# LPC11U6x register map
File version: 0.8
CPU: CM0PLUS r0p1, little endian, no MPU, no FPU, 2 interrupt priority bits
Registers are 32-bit, read-write, reset 0x0 unless marked. A register's access mark holds for its fields unless they carry their own. Offsets are from the block's base; [hi:lo] are bit positions; {n}, {i} and the like mark numbered series; 'fields as' and 'values as' point back to an identical list.

## SYSCON — System configuration (SYSCON)
Base 0x40048000
0x00 SYSMEMREMAP — System memory remap
  [1:0] MAP — System memory remap. Value 0x3 is reserved.
    0=BOOT_LOADER_MODE (Boot Loader Mode. Interrupt vectors are re-mapped to Boot ROM.); 1=USER_RAM_MODE (User RAM Mode. Interrupt vectors are re-mapped to Static RAM.); 2=USER_FLASH_MODE (User Flash Mode. Interrupt vectors are not re-mapped and reside in Flash.)
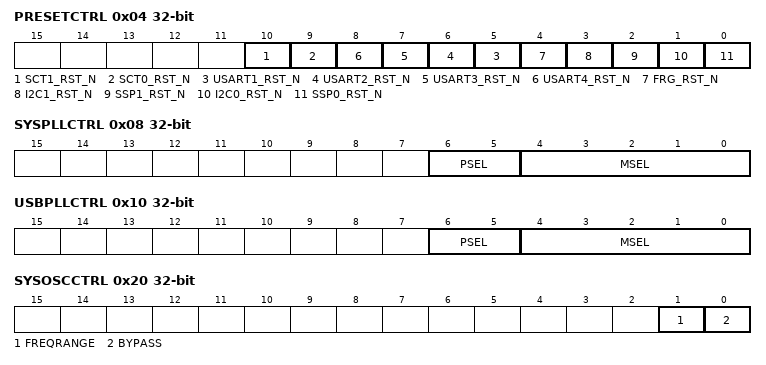
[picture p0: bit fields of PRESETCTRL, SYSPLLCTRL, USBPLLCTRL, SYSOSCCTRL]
0x04 PRESETCTRL — Peripheral reset control
  [10] SCT1_RST_N — SCT1 reset control
    0=RESET (Reset. Resets the SCT1 peripheral.); 1=CLEAR_RESET (Clear reset. SCT1 reset de-asserted.)
  [9] SCT0_RST_N — SCT0 reset control
    0=RESET (Reset. Resets the SCT0 peripheral.); 1=CLEAR_RESET (Clear reset. SCT0 reset de-asserted.)
  [n+4] USART{n}_RST_N (n=1..4) — USART{n} reset control
    0=RESET (Reset. Resets the USART{n} peripheral.); 1=CLEAR_RESET (Clear reset. USART{n} reset de-asserted.)
  [4] FRG_RST_N — FRG reset control
    0=RESET (Reset. Resets the FRG peripheral.); 1=CLEAR_RESET (Clear reset. FRG reset de-asserted.)
  [3] I2C1_RST_N — I2C1 reset control
    0=RESET (Reset. Resets the I2C1 peripheral.); 1=CLEAR_RESET (Clear reset. I2C1 reset de-asserted.)
  [2] SSP1_RST_N — SSP1 reset control
    0=RESET (Reset. Resets the SSP1 peripheral.); 1=CLEAR_RESET (Clear reset. SSP1 reset de-asserted.)
  [1] I2C0_RST_N — I2C0 reset control
    0=RESET (Reset. Resets the I2C0 peripheral.); 1=CLEAR_RESET (Clear reset. I2C0 reset de-asserted.)
  [0] SSP0_RST_N — SSP0 reset control
    0=RESET (Reset. Resets the SSP0 peripheral.); 1=CLEAR_RESET (Clear reset. SSP0 reset de-asserted.)
0x08 SYSPLLCTRL — System PLL control
  [6:5] PSEL — Post divider ratio P. The division ratio is 2 x P.
    0=P_EQ_1 (P = 1); 1=P_EQ_2 (P = 2); 2=P_EQ_4 (P = 4); 3=P_EQ_8 (P = 8)
  [4:0] MSEL — Feedback divider value. The division value M is the programmed MSEL value + 1. 00000: Division ratio M = 1 to 11111: Division ratio M = 32
0x0C SYSPLLSTAT ro — System PLL status
  [0] LOCK — PLL lock status
    0=NO_LOCK (No lock. PLL not locked); 1=LOCK (Lock. PLL locked)
0x10 USBPLLCTRL — USB PLL control
  fields as SYSPLLCTRL
0x14 USBPLLSTAT ro — USB PLL status
  fields as SYSPLLSTAT
0x1C RTCOSCCTRL reset 0x1 — RTC oscillator 32 kHz output control
  [0] RTCOSCEN — Enable the RTC 32 kHz output.
    0=DISABLED (Disabled. 32 kHz output disabled.); 1=ENABLED (Enabled. 32 kHz output enabled.)
0x20 SYSOSCCTRL — System oscillator control
  [1] FREQRANGE — Determines frequency range for Low-power oscillator.
    0=LOW (Low. 1 - 20 MHz frequency range.); 1=HIGH (High. 15 - 25 MHz frequency range.)
  [0] BYPASS — Bypass system oscillator
    0=OSCILLATOR_IS_NOT_BY (Oscillator is not bypassed.); 1=BYPASS_ENABLED (Bypass enabled. PLL input (sys_osc_clk) is fed directly from the XTALIN pin bypassing the oscillator. Use this mode when using an external clock source instead of the crystal oscillator.)
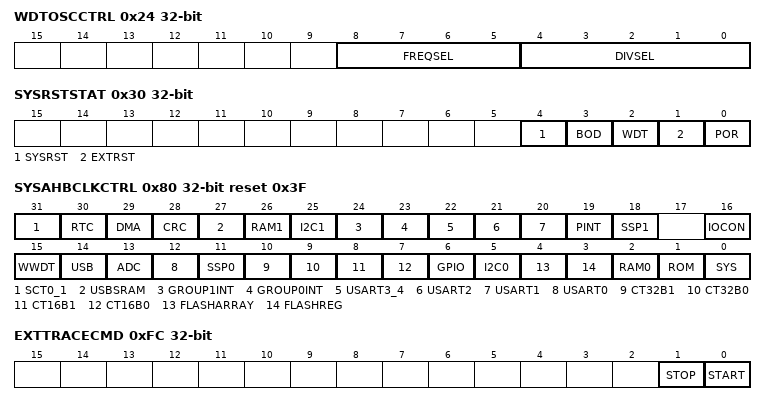
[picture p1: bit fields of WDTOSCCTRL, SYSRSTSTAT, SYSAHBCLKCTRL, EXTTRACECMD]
0x24 WDTOSCCTRL — Watchdog oscillator control
  [8:5] FREQSEL — Select watchdog oscillator analog output frequency (Fclkana).
    1=600KHz (0.6 MHz); 2=1050KHz (1.05 MHz); 3=1400KHz (1.4 MHz); 4=1750KHz (1.75 MHz); 5=2100KHz (2.1 MHz); 6=2400KHz (2.4 MHz); 7=2700KHz (2.7 MHz); 8=3000KHz (3.0 MHz); 9=3250KHz (3.25 MHz); 10=3500KHz (3.5 MHz); 11=3750KHz (3.75 MHz); 12=4000KHz (4.0 MHz); 13=4200KHz (4.2 MHz); 14=4400KHz (4.4 MHz); 15=4600KHz (4.6 MHz)
  [4:0] DIVSEL — Select divider for Fclkana. wdt_osc_clk = Fclkana/ (2 x (1 + DIVSEL)) 00000: 2 x (1 + DIVSEL) = 2 00001: 2 x (1 + DIVSEL) = 4 to 11111: 2 x (1 + DIVSEL) = 64
0x28 IRCCTRL reset 0x80 — IRC control
  [7:0] TRIM — Trim value
0x30 SYSRSTSTAT — System reset status register
  [4] SYSRST — Status of the software system reset
    0=NO_SYSTEM_RESET_DETE (No System reset detected); 1=SYSTEM_RESET_DETECTE (System reset detected)
  [3] BOD — Status of the Brown-out detect reset
    0=NO_BOD_RESET_DETECTE (No BOD reset detected); 1=BOD_RESET_DETECTED
  [2] WDT — Status of the Watchdog reset
    0=NO_WDT_RESET_DETECTE (No WDT reset detected); 1=WDT_RESET_DETECTED
  [1] EXTRST — Status of the external RESET pin
    0=NO_RESET_EVENT_DETEC (No reset event detected); 1=RESET_DETECTED
  [0] POR — POR reset status
    0=NO_POR_DETECTED; 1=POR_DETECTED
0x40 SYSPLLCLKSEL — System PLL clock source select
  [1:0] SEL — System PLL clock source
    0=IRC; 1=SYSTEM_OSCILLATOR (System oscillator. Crystal Oscillator (SYSOSC)); 3=32_KHZ_CLOCK (32 kHz clock.Select this option when the 32 kHz clock is the clock source for the main clock and select the pll input in the MAINCLKSEL register. Do not use the 32 kHz clock with the PLL.)
0x44 SYSPLLCLKUEN reset 0x1 — System PLL clock source update enable
  [0] ENA — Enable system PLL clock source update
    0=NO_CHANGE; 1=UPDATE_CLOCK_SOURCE
0x48 USBPLLCLKSEL — USB PLL clock source select
  [1:0] SEL — USB PLL clock source
    0=IRC (IRC. For full-speed USB, switch the USB PLL clock source to the system oscillator for correct USB operation. The IRC is suitable for low-speed USB operation only.); 1=SYSTEM_OSCILLATOR
0x4C USBPLLCLKUEN — USB PLL clock source update enable
  [0] ENA — Enable USB PLL clock source update
    0=NO_CHANGE; 1=UPDATE_CLOCK_SOURCE
0x70 MAINCLKSEL — Main clock source select
  [1:0] SEL — Clock source for main clock
    0=IRC_OSCILLATOR; 1=PLL_INPUT; 2=WATCHDOG_OSCILLATOR; 3=PLL_OUTPUT
0x74 MAINCLKUEN reset 0x1 — Main clock source update enable
  [0] ENA — Enable main clock source update
    0=NO_CHANGE; 1=UPDATE_CLOCK_SOURCE
0x78 SYSAHBCLKDIV reset 0x1 — System clock divider
  [7:0] DIV — System AHB clock divider values 0: System clock disabled. 1: Divide by 1. to 255: Divide by 255.
0x80 SYSAHBCLKCTRL reset 0x3F — System clock control
  [31] SCT0_1 — Enables clock for SCT0 and SCT1.
    0=DISABLE; 1=ENABLE
  [30] RTC — Enables clock for RTC register interface.
    0=DISABLE; 1=ENABLE
  [29] DMA — Enables clock for DMA.
    0=DISABLE; 1=ENABLE
  [28] CRC — Enables clock for CRC.
    0=DISABLE; 1=ENABLE
  [27] USBSRAM — Enables USB SRAM/SRAM2 block located at 0x2000 4000 to 0x2000 4800.
    0=DISABLE; 1=ENABLE
  [26] RAM1 — Enables clock for SRAM1 located at 0x2000 0000 to 0x2000 0800.
    0=DISABLE; 1=ENABLE
  [25] I2C1 — Enables clock for I2C1.
    0=DISABLE; 1=ENABLE
  [24] GROUP1INT — Enables clock to GPIO GROUP1 interrupt register interface.
    0=DISABLE; 1=ENABLE
  [23] GROUP0INT — Enables clock to GPIO GROUP0 interrupt register interface.
    0=DISABLE; 1=ENABLE
  [22] USART3_4 — Enables clock to USART3 and USART4 register interfaces.
    0=DISABLE; 1=ENABLE
  [21] USART2 — Enables clock to USART2 register interface.
    0=DISABLE; 1=ENABLE
  [20] USART1 — Enables clock to USART1 register interface.
    0=DISABLE; 1=ENABLE
  [19] PINT — Enables clock to GPIO Pin interrupt register interface.
    0=DISABLE; 1=ENABLE
  [18] SSP1 — Enables clock for SSP1.
    0=DISABLE; 1=ENABLE
  [16] IOCON — Enables clock for I/O configuration block.
    0=DISABLE; 1=ENABLE
  [15] WWDT — Enables clock for WWDT.
    0=DISABLE; 1=ENABLE
  [14] USB — Enables clock to the USB register interface.
    0=DISABLE; 1=ENABLE
  [13] ADC — Enables clock for ADC.
    0=DISABLE; 1=ENABLE
  [12] USART0 — Enables clock for USART0.
    0=DISABLE; 1=ENABLE
  [11] SSP0 — Enables clock for SSP0.
    0=DISABLE; 1=ENABLE
  [10] CT32B1 — Enables clock for 32-bit counter/timer 1.
    0=DISABLE; 1=ENABLE
  [9] CT32B0 — Enables clock for 32-bit counter/timer 0.
    0=DISABLE; 1=ENABLE
  [8] CT16B1 — Enables clock for 16-bit counter/timer 1.
    0=DISABLE; 1=ENABLE
  [7] CT16B0 — Enables clock for 16-bit counter/timer 0.
    0=DISABLE; 1=ENABLE
  [6] GPIO — Enables clock for GPIO port registers.
    0=DISABLE; 1=ENABLE
  [5] I2C0 — Enables clock for I2C.
    0=DISABLE; 1=ENABLE
  [4] FLASHARRAY — Enables clock for flash access.
    0=DISABLED; 1=ENABLED
  [3] FLASHREG — Enables clock for flash register interface.
    0=DISABLED; 1=ENABLED
  [2] RAM0 — Enables clock for Main SRAM0.
    0=DISABLE; 1=ENABLE
  [1] ROM — Enables clock for ROM.
    0=DISABLE; 1=ENABLE
  [0] SYS — This bit is read-only and always reads as 1. It configures the always-on clock for the AHB, the APB bridges, the Cortex-M0 core clocks, SYSCON, reset control, SRAM0, and the PMU. Writes to this bit are ignored.
0x94 SSP0CLKDIV — SSP0 clock divider
  [7:0] DIV — SPI0_PCLK clock divider values. 0: System clock disabled. 1: Divide by 1. to 255: Divide by 255.
0x98 USART0CLKDIV — USART0 clock divider
  [7:0] DIV — UART_PCLK clock divider values 0: Disable UART_PCLK. 1: Divide by 1. to 255: Divide by 255.
0x9C SSP1CLKDIV — SSP1 clock divider
  [7:0] DIV — SSP1_PCLK clock divider values 0: Disable SSP1_PCLK. 1: Divide by 1. to 255: Divide by 255.
0xA0 FRGCLKDIV — Clock divider for the common fractional baud rate generator of USART1, USART2, USART3, USART4
  [7:0] DIV — USART fractional baud rate generator clock divider values. 0: Clock disabled. 1: Divide by 1. to 255: Divide by 255.
0xC0 USBCLKSEL — USB clock source select
  [1:0] SEL — USB clock source. Values 0x2 and 0x3 are reserved.
    0=USB_PLL_OUT; 1=MAIN_CLOCK
0xC4 USBCLKUEN — USB clock source update enable
  [0] ENA — Enable USB clock source update
    0=NO_CHANGE; 1=UPDATE_CLOCK_SOURCE
0xC8 USBCLKDIV — USB clock source divider
  [7:0] DIV — USB clock divider values 0: Disable USB clock. 1: Divide by 1. to 255: Divide by 255.
0xE0 CLKOUTSEL — CLKOUT clock source select
  [1:0] SEL — CLKOUT clock source
    0=IRC_OSCILLATOR; 1=CRYSTAL_OSCILLATOR (Crystal oscillator (SYSOSC)); 2=WATCHDOG_OSCILLATOR; 3=MAIN_CLOCK
0xE4 CLKOUTUEN — CLKOUT clock source update enable
  [0] ENA — Enable CLKOUT clock source update
    0=NO_CHANGE; 1=UPDATE_CLOCK_SOURCE
0xE8 CLKOUTDIV — CLKOUT clock divider
  [7:0] DIV — CLKOUT clock divider values 0: Disable CLKOUT clock divider. 1: Divide by 1. to 255: Divide by 255.
0xF0 UARTFRGDIV — USART fractional generator divider value
  [7:0] DIV — Denominator of the fractional divider. DIV is equal to the programmed value +1. Always set to 0xFF to use with the fractional baud rate generator.
0xF4 UARTFRGMULT — USART fractional generator multiplier value
  [7:0] MULT — Numerator of the fractional divider. MULT is equal to the programmed value.
0xFC EXTTRACECMD — External trace buffer command register
  [1] STOP — Trace stop command. Writing a one to this bit sets the TSTOP signal in the MTB to HIGH and stops tracing if the TSTOPEN bit in the MTB master register is set to one as well.
  [0] START — Trace start command. Writing a one to this bit sets the TSTART signal to the MTB to HIGH and starts tracing if the TSTARTEN bit in the MTB master register is set to one as well.
0x100 PIOPORCAP0 ro reset not defined — POR captured PIO status 0
  [23:0] PIOSTAT — State of PIO0_23 through PIO0_0 at power-on reset
0x104 PIOPORCAP1 ro reset not defined — POR captured PIO status 1
  [31:0] PIOSTAT — State of PIO1_31 through PIO1_0 at power-on reset
0x108 PIOPORCAP2 ro reset not defined — POR captured PIO status 1
  [23:0] PIOSTAT — State of PIO2_23 through PIO2_0 at power-on reset
0x134 IOCONCLKDIV6 — Peripheral clock to the IOCON block for programmable glitch filter
  [7:0] DIV — IOCON glitch filter clock divider values 0: Disable IOCONFILTR_PCLK. 1: Divide by 1. to 255: Divide by 255.
0x138 IOCONCLKDIV5 — Peripheral clock to the IOCON block for programmable glitch filter
  fields as IOCONCLKDIV6
0x13C IOCONCLKDIV4 — Peripheral clock to the IOCON block for programmable glitch filter
  fields as IOCONCLKDIV6
0x140 IOCONCLKDIV3 — Peripheral clock to the IOCON block for programmable glitch filter
  fields as IOCONCLKDIV6
0x144 IOCONCLKDIV2 — Peripheral clock to the IOCON block for programmable glitch filter
  fields as IOCONCLKDIV6
0x148 IOCONCLKDIV1 — Peripheral clock to the IOCON block for programmable glitch filter
  fields as IOCONCLKDIV6
0x14C IOCONCLKDIV0 — Peripheral clock to the IOCON block for programmable glitch filter
  fields as IOCONCLKDIV6
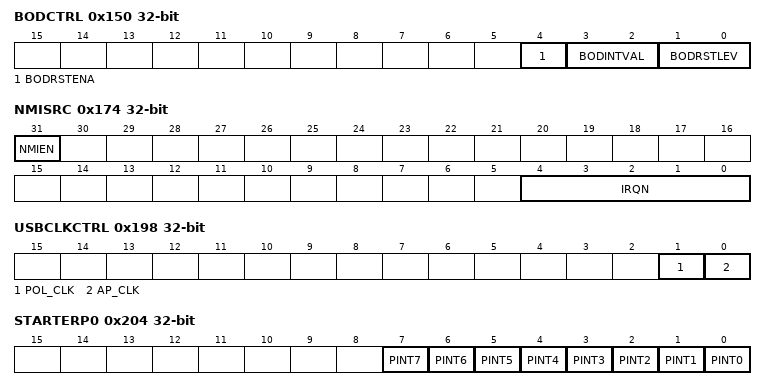
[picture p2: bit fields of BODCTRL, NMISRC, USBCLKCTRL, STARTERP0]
0x150 BODCTRL — Brown-Out Detect
  [4] BODRSTENA — BOD reset enable
    0=DISABLE_RESET_FUNCTI (Disable reset function.); 1=ENABLE_RESET_FUNCTIO (Enable reset function.)
  [3:2] BODINTVAL — BOD interrupt level
    2=LEVEL_2; 3=LEVEL_3
  [1:0] BODRSTLEV — BOD reset level
    {v}=LEVEL_{v} (v=0..3)
0x154 SYSTCKCAL reset not defined — System tick counter calibration
  [25:0] CAL — System tick timer calibration value
0x170 IRQLATENCY reset 0x10 — IRQ delay. Allows trade-off between interrupt latency and determinism.
  [7:0] LATENCY — 8-bit latency value
0x174 NMISRC — NMI Source Control
  [31] NMIEN — Write a 1 to this bit to enable the Non-Maskable Interrupt (NMI) source selected by bits 4:0.
  [4:0] IRQN — The IRQ number of the interrupt that acts as the Non-Maskable Interrupt (NMI) if bit 31 is 1. See Table 6 for the list of interrupt sources and their IRQ numbers.
{0x178+4i} PINTSEL{i} (i=0..7) — GPIO Pin Interrupt Select register 0
  [5:0] INTPIN — Pin number. PIO0_0 = 0, ..., PIO0_23 = 23, PIO1_0 = 24, ..., PIO1_31 = 55, PIO2_0 = 56, ..., PIO2_7 = 63.
0x198 USBCLKCTRL reset not defined — USB clock control
  [1] POL_CLK — USB need_clock polarity for triggering the USB wake-up interrupt
    0=FALLING_EDGE (Falling edge. Falling edge of the USB need_clock triggers the USB wake-up (default).); 1=RISING_EDGE (Rising edge. Rising edge of the USB need_clock triggers the USB wake-up.)
  [0] AP_CLK — USB need_clock signal control
    0=HARDWARE (Hardware. Under hardware control.); 1=FORCED (Forced. Forced HIGH.)
0x19C USBCLKST ro reset not defined — USB clock status
  [0] NEED_CLKST — USB need_clock signal status
    0=LOW; 1=HIGH
0x204 STARTERP0 — Start logic 0 interrupt wake-up enable register 0
  [all] fields
    0=DISABLED; 1=ENABLED
  [n] PINT{n} (n=0..7) — Pin interrupt {n} wake-up
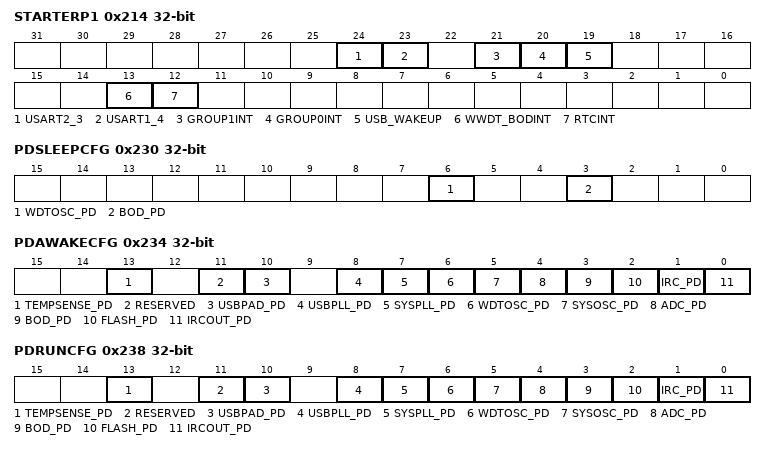
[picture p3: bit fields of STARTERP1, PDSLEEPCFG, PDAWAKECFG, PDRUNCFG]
0x214 STARTERP1 — Start logic 1 interrupt wake-up enable register 1
  [all] fields
    0=DISABLED; 1=ENABLED
  [24] USART2_3 — Combined USART2 and USART3 interrupt wake-up
  [23] USART1_4 — Combined USART1 and USART4 interrupt wake-up
  [21] GROUP1INT — GPIO GROUP1 interrupt wake-up
  [20] GROUP0INT — GPIO GROUP0 interrupt wake-up
  [19] USB_WAKEUP — USB need_clock signal wake-up
  [13] WWDT_BODINT — Combined WWDT interrupt or Brown Out Detect (BOD) interrupt wake-up
  [12] RTCINT — RTC interrupt wake-up
0x230 PDSLEEPCFG reset not defined — Power-down states in deep-sleep mode
  [6] WDTOSC_PD — Watchdog oscillator power-down control for Deep-sleep and Power-down mode
    1=POWERED_DOWN; 0=POWERED
  [3] BOD_PD — BOD power-down control for Deep-sleep and Power-down mode
    1=POWERED_DOWN; 0=POWERED
0x234 PDAWAKECFG reset not defined — Power-down states for wake-up from deep-sleep
  [13] TEMPSENSE_PD — Temperature sensor wake-up configuration
    0=POWERED; 1=POWERED_DOWN
  [11] RESERVED — Reserved. This bit must be set to one in Run mode.
  [10] USBPAD_PD — USB transceiver wake-up configuration
    0=POWERED; 1=POWERED_DOWN
  [8] USBPLL_PD — USB PLL wake-up configuration
    0=POWERED; 1=POWERED_DOWN
  [7] SYSPLL_PD — System PLL wake-up configuration
    1=POWERED_DOWN; 0=POWERED
  [6] WDTOSC_PD — Watchdog oscillator wake-up configuration
    1=POWERED_DOWN; 0=POWERED
  [5] SYSOSC_PD — Crystal oscillator wake-up configuration
    1=POWERED_DOWN; 0=POWERED
  [4] ADC_PD — ADC wake-up configuration
    1=POWERED_DOWN; 0=POWERED
  [3] BOD_PD — BOD wake-up configuration
    1=POWERED_DOWN; 0=POWERED
  [2] FLASH_PD — Flash wake-up configuration
    1=POWERED_DOWN; 0=POWERED
  [1] IRC_PD — IRC oscillator power-down wake-up configuration
    1=POWERED_DOWN; 0=POWERED
  [0] IRCOUT_PD — IRC oscillator output wake-up configuration
    1=POWERED_DOWN; 0=POWERED
0x238 PDRUNCFG reset not defined — Power configuration register
  [13] TEMPSENSE_PD — Temperature sensor wake-up configuration
    0=POWERED; 1=POWERED_DOWN
  [11] RESERVED — Reserved. This bit must be set to one in Run mode.
  [10] USBPAD_PD — USB transceiver power-down configuration
    0=POWERED; 1=POWERED_DOWN
  [8] USBPLL_PD — USB PLL power-down
    0=POWERED; 1=POWERED_DOWN
  [7] SYSPLL_PD — System PLL power-down
    0=POWERED; 1=POWERED_DOWN
  [6] WDTOSC_PD — Watchdog oscillator power-down
    0=POWERED; 1=POWERED_DOWN
  [5] SYSOSC_PD — Crystal oscillator power-down. After power-up, add a software delay of approximately 500 us before using.
    0=POWERED; 1=POWERED_DOWN
  [4] ADC_PD — ADC power-down
    0=POWERED; 1=POWERED_DOWN
  [3] BOD_PD — BOD power-down
    0=POWERED; 1=POWERED_DOWN
  [2] FLASH_PD — Flash power-down
    0=POWERED; 1=POWERED_DOWN
  [1] IRC_PD — IRC oscillator power-down
    0=POWERED; 1=POWERED_DOWN
  [0] IRCOUT_PD — IRC oscillator output power-down
    0=POWERED; 1=POWERED_DOWN
0x3F4 DEVICE_ID ro reset not defined
  [31:0] DEVICEID — PARTID
